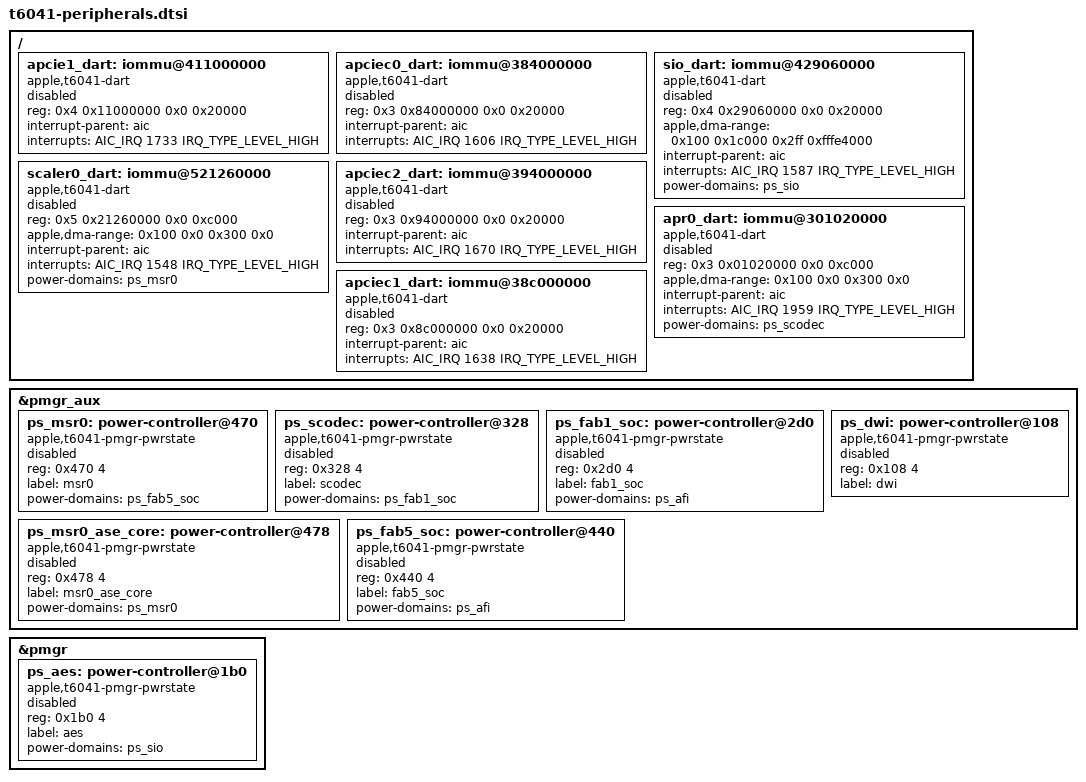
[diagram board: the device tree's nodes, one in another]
// SPDX-License-Identifier: GPL-2.0-only OR MIT
/* Restore disabled providers for the shared T604x resource descriptions. */

&pmgr_aux {
	ps_msr0: power-controller@470 {
		compatible = "apple,t6041-pmgr-pwrstate", "apple,t8103-pmgr-pwrstate";
		reg = <0x470 4>;
		#power-domain-cells = <0>;
		#reset-cells = <0>;
		label = "msr0";
		power-domains = <&ps_fab5_soc>;
		status = "disabled";
	};
};

&pmgr_aux {
	ps_scodec: power-controller@328 {
		compatible = "apple,t6041-pmgr-pwrstate", "apple,t8103-pmgr-pwrstate";
		reg = <0x328 4>;
		#power-domain-cells = <0>;
		#reset-cells = <0>;
		label = "scodec";
		power-domains = <&ps_fab1_soc>;
		status = "disabled";
	};
};

/ {
	apcie1_dart: iommu@411000000 {
		compatible = "apple,t6041-dart", "apple,t8110-dart";
		reg = <0x4 0x11000000 0x0 0x20000>;
		#iommu-cells = <1>;
		interrupt-parent = <&aic>;
		interrupts = <AIC_IRQ 1733 IRQ_TYPE_LEVEL_HIGH>;
		status = "disabled";
	};
};

&pmgr_aux {
	ps_fab1_soc: power-controller@2d0 {
		compatible = "apple,t6041-pmgr-pwrstate", "apple,t8103-pmgr-pwrstate";
		reg = <0x2d0 4>;
		#power-domain-cells = <0>;
		#reset-cells = <0>;
		label = "fab1_soc";
		power-domains = <&ps_afi>;
		status = "disabled";
	};
};

/ {
	apciec0_dart: iommu@384000000 {
		compatible = "apple,t6041-dart", "apple,t8110-dart";
		reg = <0x3 0x84000000 0x0 0x20000>;
		#iommu-cells = <1>;
		interrupt-parent = <&aic>;
		interrupts = <AIC_IRQ 1606 IRQ_TYPE_LEVEL_HIGH>;
		status = "disabled";
	};
};

/ {
	sio_dart: iommu@429060000 {
		compatible = "apple,t6041-dart", "apple,t8110-dart";
		reg = <0x4 0x29060000 0x0 0x20000>;
		#iommu-cells = <1>;
		apple,dma-range = <0x100 0x1c000 0x2ff 0xfffe4000>;
		interrupt-parent = <&aic>;
		interrupts = <AIC_IRQ 1587 IRQ_TYPE_LEVEL_HIGH>;
		power-domains = <&ps_sio>;
		status = "disabled";
	};
};

&pmgr {
	ps_aes: power-controller@1b0 {
		compatible = "apple,t6041-pmgr-pwrstate", "apple,t8103-pmgr-pwrstate";
		reg = <0x1b0 4>;
		#power-domain-cells = <0>;
		#reset-cells = <0>;
		label = "aes";
		power-domains = <&ps_sio>;
		status = "disabled";
	};
};

&pmgr_aux {
	ps_dwi: power-controller@108 {
		compatible = "apple,t6041-pmgr-pwrstate", "apple,t8103-pmgr-pwrstate";
		reg = <0x108 4>;
		#power-domain-cells = <0>;
		#reset-cells = <0>;
		label = "dwi";
		status = "disabled";
	};
};

/ {
	scaler0_dart: iommu@521260000 {
		compatible = "apple,t6041-dart", "apple,t8110-dart";
		reg = <0x5 0x21260000 0x0 0xc000>;
		#iommu-cells = <1>;
		apple,dma-range = <0x100 0x0 0x300 0x0>;
		interrupt-parent = <&aic>;
		interrupts = <AIC_IRQ 1548 IRQ_TYPE_LEVEL_HIGH>;
		power-domains = <&ps_msr0>;
		status = "disabled";
	};
};

/ {
	apciec2_dart: iommu@394000000 {
		compatible = "apple,t6041-dart", "apple,t8110-dart";
		reg = <0x3 0x94000000 0x0 0x20000>;
		#iommu-cells = <1>;
		interrupt-parent = <&aic>;
		interrupts = <AIC_IRQ 1670 IRQ_TYPE_LEVEL_HIGH>;
		status = "disabled";
	};
};

&pmgr_aux {
	ps_msr0_ase_core: power-controller@478 {
		compatible = "apple,t6041-pmgr-pwrstate", "apple,t8103-pmgr-pwrstate";
		reg = <0x478 4>;
		#power-domain-cells = <0>;
		#reset-cells = <0>;
		label = "msr0_ase_core";
		power-domains = <&ps_msr0>;
		status = "disabled";
	};
};

/ {
	apr0_dart: iommu@301020000 {
		compatible = "apple,t6041-dart", "apple,t8110-dart";
		reg = <0x3 0x01020000 0x0 0xc000>;
		#iommu-cells = <1>;
		apple,dma-range = <0x100 0x0 0x300 0x0>;
		interrupt-parent = <&aic>;
		interrupts = <AIC_IRQ 1959 IRQ_TYPE_LEVEL_HIGH>;
		power-domains = <&ps_scodec>;
		status = "disabled";
	};
};

/ {
	apciec1_dart: iommu@38c000000 {
		compatible = "apple,t6041-dart", "apple,t8110-dart";
		reg = <0x3 0x8c000000 0x0 0x20000>;
		#iommu-cells = <1>;
		interrupt-parent = <&aic>;
		interrupts = <AIC_IRQ 1638 IRQ_TYPE_LEVEL_HIGH>;
		status = "disabled";
	};
};

&pmgr_aux {
	ps_fab5_soc: power-controller@440 {
		compatible = "apple,t6041-pmgr-pwrstate", "apple,t8103-pmgr-pwrstate";
		reg = <0x440 4>;
		#power-domain-cells = <0>;
		#reset-cells = <0>;
		label = "fab5_soc";
		power-domains = <&ps_afi>;
	status = "disabled";
	};
};

#include "t604x-peripherals.dtsi"
